AUTOSAR XML (schema 00044)
package /ComponentTypes
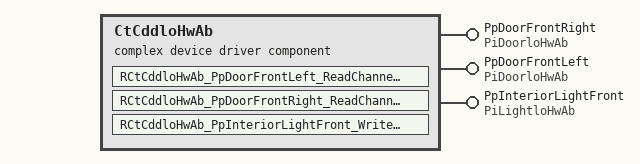
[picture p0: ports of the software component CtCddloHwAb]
  complex device driver sw component type CtCddloHwAb
    provide port PpDoorFrontRight: server-com-spec{operation=ReadChannel, queue-length=1}, provided-interface=PiDoorloHwAb
    provide port PpDoorFrontLeft: server-com-spec{operation=ReadChannel, queue-length=1}, provided-interface=PiDoorloHwAb
    provide port PpInteriorLightFront: server-com-spec{operation=WriteChannel, queue-length=1}, provided-interface=PiLightloHwAb
    behavior CtCddloHwAb_InternalBehavior
      operation invoked event OIT_RCtCddloHwAb_PpDoorFrontLeft_ReadChannelPpDoorFrontLeft_ReadChannel_PpDoorFrontLeft_ReadChannel: start-on-event=RCtCddloHwAb_PpDoorFrontLeft_ReadChannelPpDoorFrontLeft_ReadChannel, operation=PpDoorFrontLeft.ReadChannel
      operation invoked event OIT_RCtCddloHwAb_PpDoorFrontRight_ReadChannelPpDoorFrontRight_ReadChannel_PpDoorFrontRight_ReadChannel: start-on-event=RCtCddloHwAb_PpDoorFrontRight_ReadChannelPpDoorFrontRight_ReadChannel, operation=PpDoorFrontRight.ReadChannel
      operation invoked event OIT_RCtCddloHwAb_PpInteriorLightFront_WriteChannelPpInteriorLightFront_WriteChannel_PpInteriorLightFront_WriteChannel: start-on-event=RCtCddloHwAb_PpInteriorLightFront_WriteChannelPpInteriorLightFront_WriteChannel, operation=PpInteriorLightFront.WriteChannel
      runnable RCtCddloHwAb_PpDoorFrontLeft_ReadChannelPpDoorFrontLeft_ReadChannel
      runnable RCtCddloHwAb_PpDoorFrontRight_ReadChannelPpDoorFrontRight_ReadChannel
      runnable RCtCddloHwAb_PpInteriorLightFront_WriteChannelPpInteriorLightFront_WriteChannel
  swc implementation CtCddloHwAb_Implementation: behavior=CtCddloHwAb_InternalBehavior
